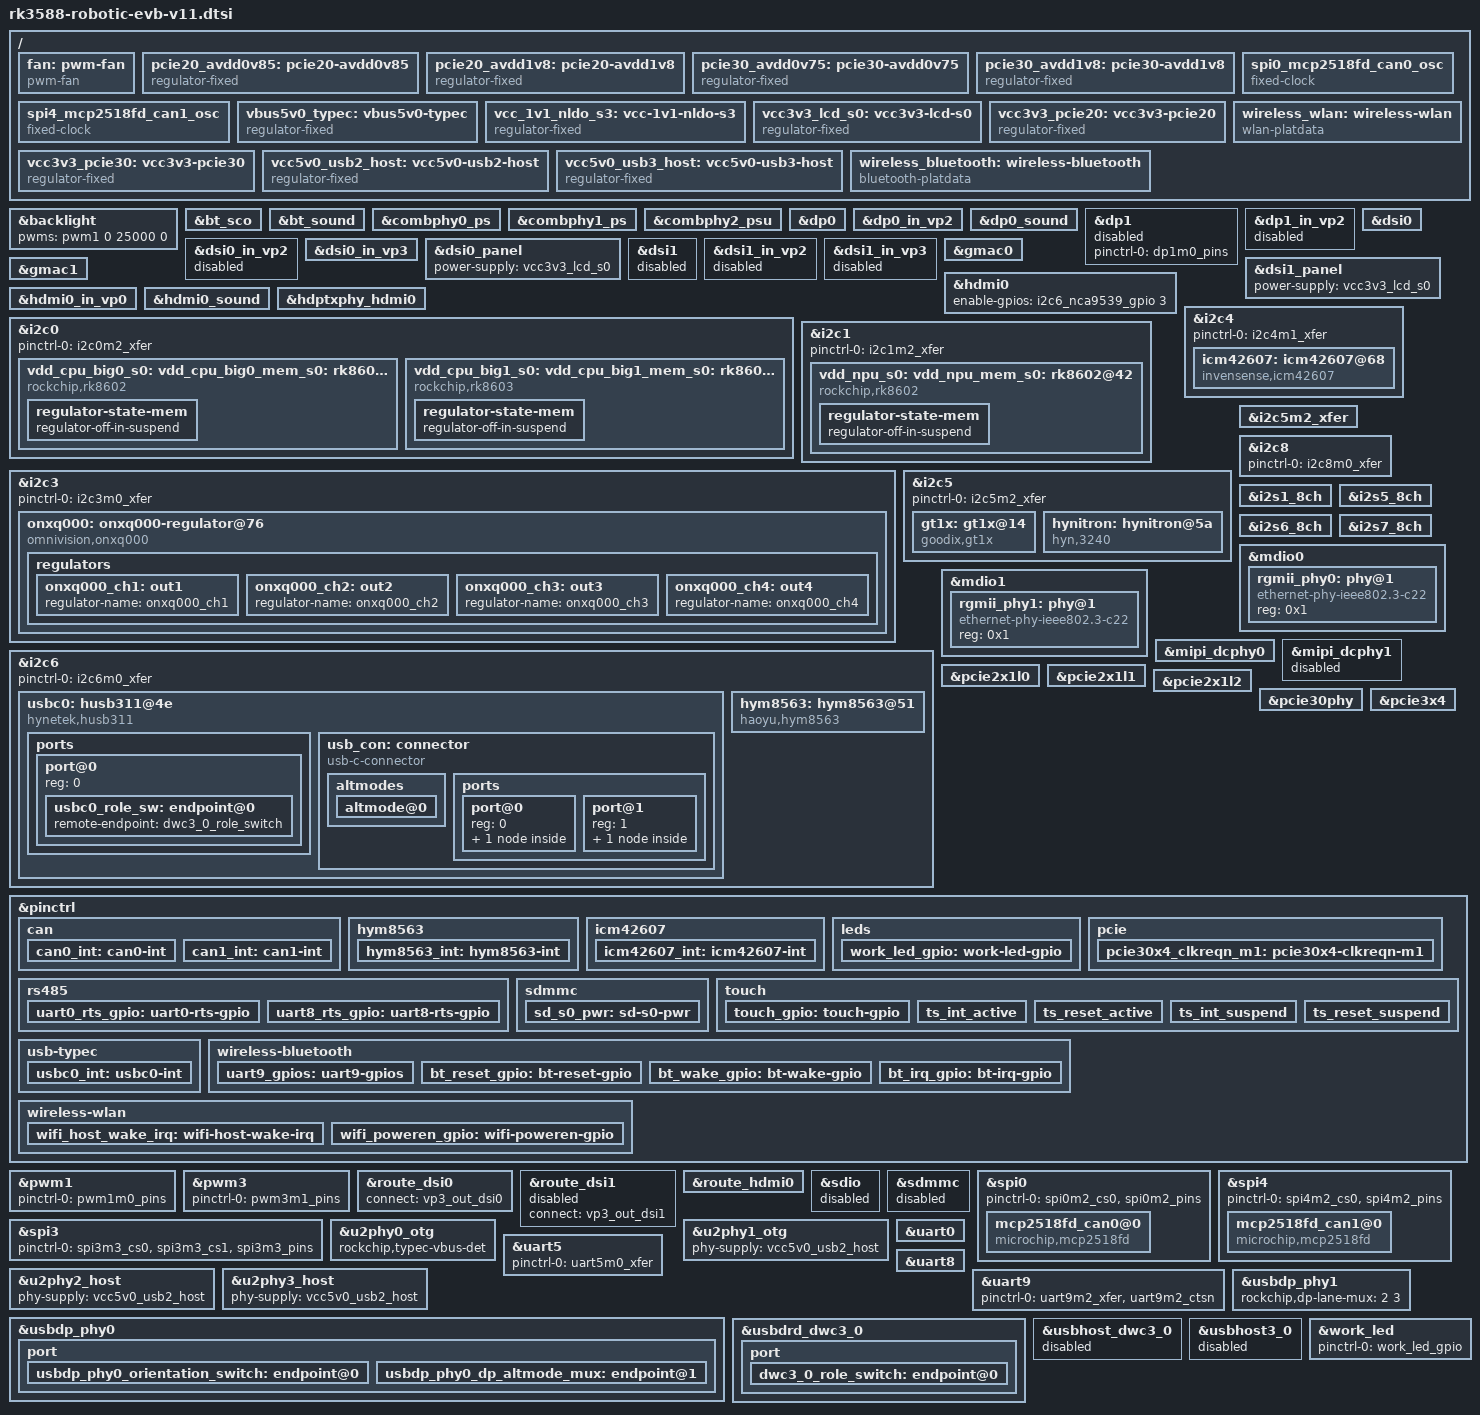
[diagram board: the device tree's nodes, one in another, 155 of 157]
// SPDX-License-Identifier: (GPL-2.0+ OR MIT)
/*
 * Copyright (c) 2025 Rockchip Electronics Co., Ltd.
 *
 */

#include "dt-bindings/usb/pd.h"
#include "rk3588.dtsi"
#include "rk3588-robotic-v11.dtsi"
#include "rk3588-rk806-single.dtsi"

/ {
	fan: pwm-fan {
		compatible = "pwm-fan";
		status = "okay";
		#cooling-cells = <2>;
		pwms = <&pwm3 0 50000 0>;
		cooling-levels = <0 50 100 150 200 255>;
		rockchip,temp-trips = <
			50000	1
			55000	2
			60000	3
			65000	4
			70000	5
		>;
	};

	pcie20_avdd0v85: pcie20-avdd0v85 {
		compatible = "regulator-fixed";
		regulator-name = "pcie20_avdd0v85";
		regulator-boot-on;
		regulator-always-on;
		regulator-min-microvolt = <850000>;
		regulator-max-microvolt = <850000>;
		vin-supply = <&vdd_0v85_s0>;
	};

	pcie20_avdd1v8: pcie20-avdd1v8 {
		compatible = "regulator-fixed";
		regulator-name = "pcie20_avdd1v8";
		regulator-boot-on;
		regulator-always-on;
		regulator-min-microvolt = <1800000>;
		regulator-max-microvolt = <1800000>;
		vin-supply = <&avcc_1v8_s0>;
	};

	pcie30_avdd0v75: pcie30-avdd0v75 {
		compatible = "regulator-fixed";
		regulator-name = "pcie30_avdd0v75";
		regulator-boot-on;
		regulator-always-on;
		regulator-min-microvolt = <750000>;
		regulator-max-microvolt = <750000>;
		vin-supply = <&avdd_0v75_s0>;
	};

	pcie30_avdd1v8: pcie30-avdd1v8 {
		compatible = "regulator-fixed";
		regulator-name = "pcie30_avdd1v8";
		regulator-boot-on;
		regulator-always-on;
		regulator-min-microvolt = <1800000>;
		regulator-max-microvolt = <1800000>;
		vin-supply = <&avcc_1v8_s0>;
	};

	spi0_mcp2518fd_can0_osc: spi0_mcp2518fd_can0_osc {
		compatible = "fixed-clock";
		#clock-cells = <0>;
		clock-frequency = <40000000>; // 40 MHz
		clock-output-names = "spi0_mcp2518fd_can0_osc";
	};

	spi4_mcp2518fd_can1_osc: spi4_mcp2518fd_can1_osc {
		compatible = "fixed-clock";
		#clock-cells = <0>;
		clock-frequency = <40000000>; // 40 MHz
		clock-output-names = "spi4_mcp2518fd_can1_osc";
	};

	vbus5v0_typec: vbus5v0-typec {
		compatible = "regulator-fixed";
		regulator-name = "vbus5v0_typec";
		regulator-min-microvolt = <5000000>;
		regulator-max-microvolt = <5000000>;
		enable-active-high;
		gpio = <&i2c6_nca9539_gpio 0 GPIO_ACTIVE_HIGH>;
		vin-supply = <&vcc5v0_sys>;
	};

	vcc_1v1_nldo_s3: vcc-1v1-nldo-s3 {
		compatible = "regulator-fixed";
		regulator-name = "vcc_1v1_nldo_s3";
		regulator-always-on;
		regulator-boot-on;
		regulator-min-microvolt = <1100000>;
		regulator-max-microvolt = <1100000>;
		vin-supply = <&vcc5v0_sys>;
	};

	vcc3v3_lcd_s0: vcc3v3-lcd-s0 {
		compatible = "regulator-fixed";
		regulator-name = "vcc3v3_lcd_s0";
		regulator-boot-on;
		enable-active-high;
		/* pin22 for 30pin MIPI LCD */
		gpio = <&gpio4 RK_PB5 GPIO_ACTIVE_HIGH>;
		vin-supply = <&vcc_3v3_s3>;
	};

	vcc3v3_pcie20: vcc3v3-pcie20 {
		compatible = "regulator-fixed";
		regulator-always-on;
		regulator-boot-on;
		regulator-name = "vcc3v3_pcie20";
		regulator-min-microvolt = <3300000>;
		regulator-max-microvolt = <3300000>;
		enable-active-high;
		gpios = <&i2c4_nca9539_gpio 9 GPIO_ACTIVE_HIGH>;
		startup-delay-us = <5000>;
		vin-supply = <&vcc12v_dcin>;
	};

	vcc3v3_pcie30: vcc3v3-pcie30 {
		compatible = "regulator-fixed";
		regulator-always-on;
		regulator-boot-on;
		regulator-name = "vcc3v3_pcie30";
		regulator-min-microvolt = <3300000>;
		regulator-max-microvolt = <3300000>;
		enable-active-high;
		gpios = <&i2c4_nca9539_gpio 10 GPIO_ACTIVE_HIGH>;
		startup-delay-us = <5000>;
		vin-supply = <&vcc12v_dcin>;
	};

	vcc5v0_usb2_host: vcc5v0-usb2-host {
		compatible = "regulator-fixed";
		regulator-name = "vcc5v0_usb2_host";
		regulator-always-on;
		regulator-boot-on;
		regulator-min-microvolt = <5000000>;
		regulator-max-microvolt = <5000000>;
		enable-active-high;
		gpio = <&i2c6_nca9539_gpio 1 GPIO_ACTIVE_HIGH>;
		vin-supply = <&vcc5v0_sys>;
	};

	vcc5v0_usb3_host: vcc5v0-usb3-host {
		compatible = "regulator-fixed";
		regulator-name = "vcc5v0_usb3_host";
		regulator-always-on;
		regulator-boot-on;
		regulator-min-microvolt = <5000000>;
		regulator-max-microvolt = <5000000>;
		enable-active-high;
		gpio = <&i2c6_nca9539_gpio 2 GPIO_ACTIVE_HIGH>;
		vin-supply = <&vcc5v0_sys>;
	};

	wireless_bluetooth: wireless-bluetooth {
		compatible = "bluetooth-platdata";
		bt_port = "/dev/ttyS9";
		clocks = <&hym8563>;
		clock-names = "ext_clock";
		uart_rts_gpios = <&gpio3 RK_PD2 GPIO_ACTIVE_LOW>;
		pinctrl-names = "default", "rts_gpio";
		pinctrl-0 = <&uart9m2_rtsn>, <&bt_reset_gpio>, <&bt_wake_gpio>, <&bt_irq_gpio>;
		pinctrl-1 = <&uart9_gpios>;
		BT,reset_gpio    = <&gpio0 RK_PC6 GPIO_ACTIVE_HIGH>;
		BT,wake_gpio     = <&gpio0 RK_PC5 GPIO_ACTIVE_HIGH>;
		BT,wake_host_irq = <&gpio0 RK_PA0 GPIO_ACTIVE_HIGH>;
		status = "okay";
	};

	wireless_wlan: wireless-wlan {
		compatible = "wlan-platdata";
		wifi_chip_type = "ap6275p";
		pinctrl-names = "default";
		pinctrl-0 = <&wifi_host_wake_irq>, <&wifi_poweren_gpio>;
		WIFI,host_wake_irq = <&gpio0 RK_PB2 GPIO_ACTIVE_HIGH>;
		WIFI,poweren_gpio = <&gpio0 RK_PC4 GPIO_ACTIVE_HIGH>;
		status = "okay";
	};
};

&backlight {
	pwms = <&pwm1 0 25000 0>;
	status = "okay";
};

&bt_sco {
	status = "okay";
};

&bt_sound {
	status = "okay";
};

&combphy0_ps {
	status = "okay";
};

&combphy1_ps {
	status = "okay";
};

&combphy2_psu {
	status = "okay";
};

&dp0 {
	status = "okay";
};

&dp0_in_vp2 {
	status = "okay";
};

&dp0_sound{
	status = "okay";
};

&dp1 {
	pinctrl-names = "default";
	pinctrl-0 = <&dp1m0_pins>;
	status = "disabled";
};

&dp1_in_vp2 {
	status = "disabled";
};

/*
 * mipi_dcphy0 needs to be enabled
 * when dsi0 is enabled
 */
&dsi0 {
	status = "okay";
};

&dsi0_in_vp2 {
	status = "disabled";
};

&dsi0_in_vp3 {
	status = "okay";
};

&dsi0_panel {
	/* no reset in hardware */
	power-supply = <&vcc3v3_lcd_s0>;
};

/*
 * mipi_dcphy1 needs to be enabled
 * when dsi1 is enabled
 */
&dsi1 {
	status = "disabled";
};

&dsi1_in_vp2 {
	status = "disabled";
};

&dsi1_in_vp3 {
	status = "disabled";
};

&dsi1_panel {
	/* no reset in hardware */
	power-supply = <&vcc3v3_lcd_s0>;

	/*
	 * because in hardware, the two screens share the reset pin,
	 * so reset-gpios need only in dsi1 enable and dsi0 disabled
	 * case.
	 */
};

&gmac0 {
	/* Use rgmii-rxid mode to disable rx delay inside Soc */
	phy-mode = "rgmii-rxid";
	clock_in_out = "output";

	snps,reset-gpio = <&gpio3 RK_PA6 GPIO_ACTIVE_LOW>;
	snps,reset-active-low;
	/* Reset time is 20ms, 100ms for rtl8211f */
	snps,reset-delays-us = <0 20000 100000>;

	pinctrl-names = "default";
	pinctrl-0 = <&gmac0_miim
		     &gmac0_tx_bus2
		     &gmac0_rx_bus2
		     &gmac0_rgmii_clk
		     &gmac0_rgmii_bus>;

	tx_delay = <0x32>;
	/* rx_delay = <0x3f>; */

	phy-handle = <&rgmii_phy0>;
	status = "okay";
};

&gmac1 {
	/* Use rgmii-rxid mode to disable rx delay inside Soc */
	phy-mode = "rgmii-rxid";
	clock_in_out = "output";

	snps,reset-gpio = <&gpio3 RK_PB7 GPIO_ACTIVE_LOW>;
	snps,reset-active-low;
	/* Reset time is 20ms, 100ms for rtl8211f */
	snps,reset-delays-us = <0 20000 100000>;

	pinctrl-names = "default";
	pinctrl-0 = <&gmac1_miim
		     &gmac1_tx_bus2
		     &gmac1_rx_bus2
		     &gmac1_rgmii_clk
		     &gmac1_rgmii_bus>;

	tx_delay = <0x31>;
	/* rx_delay = <0x3f>; */

	phy-handle = <&rgmii_phy1>;
	status = "okay";
};

&hdmi0 {
	enable-gpios = <&i2c6_nca9539_gpio 3 GPIO_ACTIVE_HIGH>;
	status = "okay";
};

&hdmi0_in_vp0 {
	status = "okay";
};

&hdmi0_sound {
	status = "okay";
};

&hdptxphy_hdmi0 {
	status = "okay";
};

&i2c0 {
	pinctrl-names = "default";
	pinctrl-0 = <&i2c0m2_xfer>;
	status = "okay";

	vdd_cpu_big0_s0: vdd_cpu_big0_mem_s0: rk8602@42 {
		compatible = "rockchip,rk8602";
		reg = <0x42>;
		vin-supply = <&vcc5v0_sys>;
		regulator-compatible = "rk860x-reg";
		regulator-name = "vdd_cpu_big0_s0";
		regulator-min-microvolt = <550000>;
		regulator-max-microvolt = <1050000>;
		regulator-ramp-delay = <2300>;
		rockchip,suspend-voltage-selector = <1>;
		regulator-boot-on;
		regulator-always-on;
		regulator-state-mem {
			regulator-off-in-suspend;
		};
	};

	vdd_cpu_big1_s0: vdd_cpu_big1_mem_s0: rk8603@43 {
		compatible = "rockchip,rk8603";
		reg = <0x43>;
		vin-supply = <&vcc5v0_sys>;
		regulator-compatible = "rk860x-reg";
		regulator-name = "vdd_cpu_big1_s0";
		regulator-min-microvolt = <550000>;
		regulator-max-microvolt = <1050000>;
		regulator-ramp-delay = <2300>;
		rockchip,suspend-voltage-selector = <1>;
		regulator-boot-on;
		regulator-always-on;
		regulator-state-mem {
			regulator-off-in-suspend;
		};
	};
};

&i2c1 {
	pinctrl-names = "default";
	pinctrl-0 = <&i2c1m2_xfer>;
	status = "okay";

	vdd_npu_s0: vdd_npu_mem_s0: rk8602@42 {
		compatible = "rockchip,rk8602";
		reg = <0x42>;
		vin-supply = <&vcc5v0_sys>;
		regulator-compatible = "rk860x-reg";
		regulator-name = "vdd_npu_s0";
		regulator-min-microvolt = <550000>;
		regulator-max-microvolt = <950000>;
		regulator-ramp-delay = <2300>;
		rockchip,suspend-voltage-selector = <1>;
		regulator-boot-on;
		regulator-always-on;
		regulator-state-mem {
			regulator-off-in-suspend;
		};
	};
};

&i2c3 {
	pinctrl-names = "default";
	pinctrl-0 = <&i2c3m0_xfer>;
	status = "okay";

	onxq000: onxq000-regulator@76 {
		compatible = "omnivision,onxq000";
		status = "okay";
		reg = <0x76>;
		vin-supply = <&vcc12v_dcin>;

		/* If onxq000 is controlled by GPIO, the properties below must be defined */
		//onxq000,control-by-gpio;
		//pinctrl-names = "default";
		//pinctrl-0 = <&onxq000_gpio>;
		//ena-gpios = <&gpio_in1>, <&gpio_in2>, <&gpio_in3>, <&gpio_in4>;

		regulators {
			onxq000_ch1: out1 {
				regulator-name = "onxq000_ch1";
			};

			onxq000_ch2: out2 {
				regulator-name = "onxq000_ch2";
			};

			onxq000_ch3: out3 {
				regulator-name = "onxq000_ch3";
			};

			onxq000_ch4: out4 {
				regulator-name = "onxq000_ch4";
			};
		};
	};
};

&i2c4 {
	pinctrl-names = "default";
	pinctrl-0 = <&i2c4m1_xfer>;
	status = "okay";

	icm42607: icm42607@68 {
		compatible = "invensense,icm42607";
		reg = <0x68>;
		pinctrl-names = "default";
		pinctrl-0 = <&icm42607_int>;
		int1-gpio = <&gpio0 RK_PA4 GPIO_ACTIVE_HIGH>;
		interrupt-parent = <&gpio0>;
		interrupts = <4 IRQ_TYPE_EDGE_FALLING>;
		status = "okay";
	};
};

&i2c5 {
	pinctrl-names = "default";
	pinctrl-0 = <&i2c5m2_xfer>;
	status = "okay";

	gt1x: gt1x@14 {
		compatible = "goodix,gt1x";
		reg = <0x14>;
		pinctrl-names = "default";
		pinctrl-0 = <&touch_gpio>;
		goodix,rst-gpio = <&gpio3 RK_PC1 GPIO_ACTIVE_HIGH>;
		goodix,irq-gpio = <&gpio3 RK_PC0 IRQ_TYPE_LEVEL_LOW>;
		power-supply = <&vcc3v3_lcd_s0>;
	};

	hynitron: hynitron@5a {
		compatible = "hyn,3240";
		reg = <0x5a>;

		pinctrl-names = "ts_active","ts_suspend";
		pinctrl-0 = <&ts_int_active &ts_reset_active>;
		pinctrl-1 = <&ts_int_suspend &ts_reset_suspend>;

		reset-gpios = <&gpio3 RK_PC1 GPIO_ACTIVE_HIGH>;
		irq-gpios = <&gpio3 RK_PC0 GPIO_ACTIVE_LOW>;

		max-touch-number = <5>;
		display-coords = <0 0 1080 1920>;
		pos-swap = <0>;
		posx-reverse = <0>;
		posy-reverse = <0>;
	};
};

&i2c5m2_xfer {
	rockchip,pins =
	/* i2c5_scl_m2 for TP */
	<4 RK_PA6 9 &pcfg_pull_up>,
	/* i2c5_sda_m2 for TP */
	<4 RK_PA7 9 &pcfg_pull_up>;
};

&i2c6 {
	pinctrl-names = "default";
	pinctrl-0 = <&i2c6m0_xfer>;
	status = "okay";

	usbc0: husb311@4e {
		compatible = "hynetek,husb311";
		reg = <0x4e>;
		interrupt-parent = <&gpio2>;
		interrupts = <RK_PC4 IRQ_TYPE_LEVEL_LOW>;
		pinctrl-names = "default";
		pinctrl-0 = <&usbc0_int>;
		vbus-supply = <&vbus5v0_typec>;
		status = "okay";

		ports {
			#address-cells = <1>;
			#size-cells = <0>;

			port@0 {
				reg = <0>;
				usbc0_role_sw: endpoint@0 {
					remote-endpoint = <&dwc3_0_role_switch>;
				};
			};
		};

		usb_con: connector {
			compatible = "usb-c-connector";
			label = "USB-C";
			data-role = "dual";
			power-role = "dual";
			try-power-role = "sink";
			op-sink-microwatt = <1000000>;
			sink-pdos =
				<PDO_FIXED(5000, 1000, PDO_FIXED_USB_COMM)>;
			source-pdos =
				<PDO_FIXED(5000, 3000, PDO_FIXED_USB_COMM)>;

			altmodes {
				#address-cells = <1>;
				#size-cells = <0>;

				altmode@0 {
					reg = <0>;
					svid = <0xff01>;
					vdo = <0xffffffff>;
				};
			};

			ports {
				#address-cells = <1>;
				#size-cells = <0>;

				port@0 {
					reg = <0>;
					usbc0_orien_sw: endpoint {
						remote-endpoint = <&usbdp_phy0_orientation_switch>;
					};
				};

				port@1 {
					reg = <1>;
					dp_altmode_mux: endpoint {
						remote-endpoint = <&usbdp_phy0_dp_altmode_mux>;
					};
				};
			};
		};
	};

	hym8563: hym8563@51 {
		compatible = "haoyu,hym8563";
		reg = <0x51>;
		#clock-cells = <0>;
		clock-frequency = <32768>;
		clock-output-names = "hym8563";
		pinctrl-names = "default";
		pinctrl-0 = <&hym8563_int>;
		interrupt-parent = <&gpio0>;
		interrupts = <RK_PD3 IRQ_TYPE_LEVEL_LOW>;
		wakeup-source;
	};
};

&i2c8 {
	pinctrl-names = "default";
	pinctrl-0 = <&i2c8m0_xfer>;
	status = "okay";
};

&i2s1_8ch {
	pinctrl-0 = <&i2s1m0_lrck
		     &i2s1m0_sclk
		     &i2s1m0_sdi0
		     &i2s1m0_sdo1>;
	status = "okay";
};

&i2s5_8ch {
	status = "okay";
};

&i2s6_8ch {
	status = "okay";
};

&i2s7_8ch {
	status = "okay";
};

&mdio0 {
	rgmii_phy0: phy@1 {
		compatible = "ethernet-phy-ieee802.3-c22";
		reg = <0x1>;
	};
};

&mdio1 {
	rgmii_phy1: phy@1 {
		compatible = "ethernet-phy-ieee802.3-c22";
		reg = <0x1>;
	};
};

&mipi_dcphy0 {
	status = "okay";
};

&mipi_dcphy1 {
	status = "disabled";
};

&pcie2x1l0 {
	reset-gpios = <&gpio1 RK_PA4 GPIO_ACTIVE_HIGH>;
	vpcie3v3-supply = <&vcc3v3_pcie20>;
	status = "okay";
};

&pcie2x1l1 {
	reset-gpios = <&gpio4 RK_PC3 GPIO_ACTIVE_HIGH>;
	rockchip,skip-scan-in-resume;
	status = "okay";
};

&pcie2x1l2 {
	reset-gpios = <&gpio3 RK_PD1 GPIO_ACTIVE_HIGH>;
	vpcie3v3-supply = <&vcc3v3_pcie20>;
	status = "okay";
};

&pcie30phy {
	rockchip,pcie30-phymode = <PHY_MODE_PCIE_AGGREGATION>;
	status = "okay";
};

&pcie3x4 {
	reset-gpios = <&gpio4 RK_PB6 GPIO_ACTIVE_HIGH>;
	vpcie3v3-supply = <&vcc3v3_pcie30>;
	pinctrl-names = "default";
	pinctrl-0 = <&pcie30x4_clkreqn_m1>;
	status = "okay";
};

&pinctrl {
	can {
		can0_int: can0-int {
			rockchip,pins = <4 RK_PD0 RK_FUNC_GPIO &pcfg_pull_up>;
		};
		can1_int: can1-int {
			rockchip,pins = <4 RK_PD1 RK_FUNC_GPIO &pcfg_pull_up>;
		};
	};

	hym8563 {
		hym8563_int: hym8563-int {
			rockchip,pins = <0 RK_PD3 RK_FUNC_GPIO &pcfg_pull_up>;
		};
	};

	icm42607 {
		icm42607_int: icm42607-int {
			rockchip,pins = <0 RK_PA4 RK_FUNC_GPIO &pcfg_pull_up>;
		};
	};

	leds {
		work_led_gpio: work-led-gpio {
			rockchip,pins = <1 RK_PC6 RK_FUNC_GPIO &pcfg_pull_down>;
		};
	};

	pcie {
		pcie30x4_clkreqn_m1: pcie30x4-clkreqn-m1 {
			rockchip,pins = <4 RK_PB4 RK_FUNC_GPIO &pcfg_output_low>;
		};
	};

	rs485 {
		uart0_rts_gpio: uart0-rts-gpio {
			rockchip,pins = <1 RK_PA6 RK_FUNC_GPIO &pcfg_pull_up>;
		};

		uart8_rts_gpio: uart8-rts-gpio {
			rockchip,pins = <1 RK_PA7 RK_FUNC_GPIO &pcfg_pull_up>;
		};
	};

	sdmmc {
		sd_s0_pwr: sd-s0-pwr {
			rockchip,pins = <0 RK_PB7 RK_FUNC_GPIO &pcfg_pull_up>;
		};
	};

	touch {
		touch_gpio: touch-gpio {
			rockchip,pins =
				<3 RK_PC1 RK_FUNC_GPIO &pcfg_pull_down>,
				<3 RK_PC0 RK_FUNC_GPIO &pcfg_pull_up>;
		};

		ts_int_active: ts_int_active {
			rockchip,pins = <3 RK_PC0 RK_FUNC_GPIO &pcfg_pull_up>;
		};

		ts_reset_active: ts_reset_active {
			rockchip,pins = <3 RK_PC1 RK_FUNC_GPIO &pcfg_pull_up>;
		};

		ts_int_suspend: ts_int_suspend {
			rockchip,pins = <3 RK_PC0 RK_FUNC_GPIO &pcfg_pull_down>;
		};

		ts_reset_suspend: ts_reset_suspend {
			rockchip,pins = <3 RK_PC1 RK_FUNC_GPIO &pcfg_pull_down>;
		};
	};

	usb-typec {
		usbc0_int: usbc0-int {
			rockchip,pins = <2 RK_PC4 RK_FUNC_GPIO &pcfg_pull_up>;
		};
	};

	wireless-bluetooth {
		uart9_gpios: uart9-gpios {
			rockchip,pins = <3 RK_PD2 RK_FUNC_GPIO &pcfg_pull_none>;
		};

		bt_reset_gpio: bt-reset-gpio {
			rockchip,pins = <0 RK_PC6 RK_FUNC_GPIO &pcfg_pull_none>;
		};

		bt_wake_gpio: bt-wake-gpio {
			rockchip,pins = <0 RK_PC5 RK_FUNC_GPIO &pcfg_pull_none>;
		};

		bt_irq_gpio: bt-irq-gpio {
			rockchip,pins = <0 RK_PA0 RK_FUNC_GPIO &pcfg_pull_none>;
		};
	};

	wireless-wlan {
		wifi_host_wake_irq: wifi-host-wake-irq {
			rockchip,pins = <0 RK_PB2 RK_FUNC_GPIO &pcfg_pull_down>;
		};
		wifi_poweren_gpio: wifi-poweren-gpio {
			rockchip,pins = <0 RK_PC4 RK_FUNC_GPIO &pcfg_output_high>;
		};
	};
};

&pwm1 {
	pinctrl-0 = <&pwm1m0_pins>;
	status = "okay";
};

&pwm3 {
	pinctrl-0 = <&pwm3m1_pins>;
	status = "okay";
};

&route_dsi0 {
	status = "okay";
	connect = <&vp3_out_dsi0>;
};

&route_dsi1 {
	status = "disabled";
	connect = <&vp3_out_dsi1>;
};

&route_hdmi0 {
	status = "okay";
};

&sdio {
	status = "disabled";
};

&sdmmc {
	status = "disabled";
};

&spi0 {
	pinctrl-0 = <&spi0m2_cs0 &spi0m2_pins>;
	status = "okay";

	mcp2518fd_can0@0 {
		compatible = "microchip,mcp2518fd";
		reg = <0>;
		spi-max-frequency = <10000000>;
		pinctrl-names = "default";
		pinctrl-0 = <&can0_int>;
		interrupt-parent = <&gpio4>;
		interrupts = <RK_PD0 IRQ_TYPE_LEVEL_LOW>;
		clocks = <&spi0_mcp2518fd_can0_osc>;
		clock-names = "osc";
		status = "okay";
	};
};

&spi3 {
	pinctrl-0 = <&spi3m3_cs0 &spi3m3_cs1 &spi3m3_pins>;
	status = "okay";
};

&spi4 {
	pinctrl-0 = <&spi4m2_cs0 &spi4m2_pins>;
	status = "okay";

	mcp2518fd_can1@0 {
		compatible = "microchip,mcp2518fd";
		reg = <0>;
		spi-max-frequency = <10000000>;
		pinctrl-names = "default";
		pinctrl-0 = <&can1_int>;
		interrupt-parent = <&gpio4>;
		interrupts = <RK_PD1 IRQ_TYPE_LEVEL_LOW>;
		clocks = <&spi4_mcp2518fd_can1_osc>;
		clock-names = "osc";
		status = "okay";
	};
};

&u2phy0_otg {
	rockchip,typec-vbus-det;
};

&u2phy1_otg {
	phy-supply = <&vcc5v0_usb2_host>;
};

&u2phy2_host {
	phy-supply = <&vcc5v0_usb2_host>;
};

&u2phy3_host {
	phy-supply = <&vcc5v0_usb2_host>;
};

&uart0 {
	pinctrl-names = "default";
	pinctrl-0 = <&uart0m2_xfer &uart0_rts_gpio>;
	rs485-de-gpios = <&gpio1 RK_PA6 GPIO_ACTIVE_HIGH>;
	linux,rs485-enabled-at-boot-time;
	rs485-rts-active-low;
	status = "okay";
};

&uart5 {
	pinctrl-names = "default";
	pinctrl-0 = <&uart5m0_xfer>;
	status = "okay";
};

&uart8 {
	pinctrl-names = "default";
	pinctrl-0 = <&uart8m0_xfer &uart8_rts_gpio>;
	rs485-de-gpios = <&gpio1 RK_PA7 GPIO_ACTIVE_HIGH>;
	linux,rs485-enabled-at-boot-time;
	rs485-rts-active-low;
	status = "okay";
};

&uart9 {
	pinctrl-names = "default";
	pinctrl-0 = <&uart9m2_xfer &uart9m2_ctsn>;
	status = "okay";
};

&usbdp_phy0 {
	orientation-switch;
	svid = <0xff01>;
	sbu1-dc-gpios = <&gpio4 RK_PD2 GPIO_ACTIVE_HIGH>;
	sbu2-dc-gpios = <&gpio4 RK_PD3 GPIO_ACTIVE_HIGH>;

	port {
		#address-cells = <1>;
		#size-cells = <0>;
		usbdp_phy0_orientation_switch: endpoint@0 {
			reg = <0>;
			remote-endpoint = <&usbc0_orien_sw>;
		};

		usbdp_phy0_dp_altmode_mux: endpoint@1 {
			reg = <1>;
			remote-endpoint = <&dp_altmode_mux>;
		};
	};
};

&usbdp_phy1 {
	rockchip,dp-lane-mux = <2 3>;
};

&usbdrd_dwc3_0 {
	dr_mode = "otg";
	usb-role-switch;
	port {
		#address-cells = <1>;
		#size-cells = <0>;
		dwc3_0_role_switch: endpoint@0 {
			reg = <0>;
			remote-endpoint = <&usbc0_role_sw>;
		};
	};
};

&usbhost_dwc3_0 {
	status = "disabled";
};

&usbhost3_0 {
	status = "disabled";
};

&work_led {
	pinctrl-names = "default";
	pinctrl-0 = <&work_led_gpio>;
};
